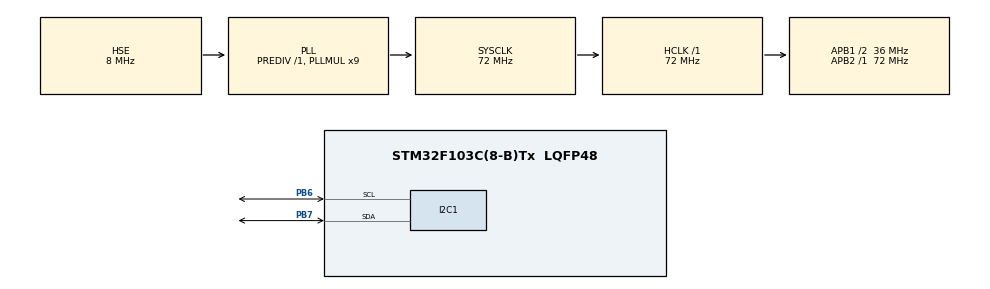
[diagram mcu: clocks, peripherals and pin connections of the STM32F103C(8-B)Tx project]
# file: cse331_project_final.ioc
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Mcu.Family=STM32F1
Mcu.Name=STM32F103C(8-B)Tx
Mcu.Package=LQFP48
NVIC.PriorityGroup=NVIC_PRIORITYGROUP_4
PA13.Mode=Serial_Wire
PA13.Signal=SYS_JTMS-SWDIO
PA14.Mode=Serial_Wire
PA14.Signal=SYS_JTCK-SWCLK
PB6.Mode=I2C
PB6.Signal=I2C1_SCL
PB7.Mode=I2C
PB7.Signal=I2C1_SDA
PD0-OSC_IN.Mode=HSE-External-Oscillator
PD0-OSC_IN.Signal=RCC_OSC_IN
PD1-OSC_OUT.Mode=HSE-External-Oscillator
PD1-OSC_OUT.Signal=RCC_OSC_OUT
ProjectManager.HeapSize=0x200
ProjectManager.StackSize=0x400
ProjectManager.TargetToolchain=STM32CubeIDE
RCC.AHBFreq_Value=72000000
RCC.APB1CLKDivider=RCC_HCLK_DIV2
RCC.APB1Freq_Value=36000000
RCC.APB1TimFreq_Value=72000000
RCC.APB2Freq_Value=72000000
RCC.APB2TimFreq_Value=72000000
RCC.HCLKFreq_Value=72000000
RCC.PLLMUL=RCC_PLL_MUL9
RCC.PLLSourceVirtual=RCC_PLLSOURCE_HSE
RCC.SYSCLKFreq_VALUE=72000000
RCC.SYSCLKSource=RCC_SYSCLKSOURCE_PLLCLK
RCC.USBFreq_Value=72000000
TIM1.Prescaler=71
VP_TIM1_VS_ClockSourceINT.Mode=Internal
board=custom

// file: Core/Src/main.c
/* USER CODE BEGIN Header */
/**
  ******************************************************************************
  * @file           : main.c
  * @brief          : Main program body
  ******************************************************************************
  * @attention
  *
  * Copyright (c) 2023 STMicroelectronics.
  * All rights reserved.
  *
  * This software is licensed under terms that can be found in the LICENSE file
  * in the root directory of this software component.
  * If no LICENSE file comes with this software, it is provided AS-IS.
  *
  ******************************************************************************
  */
/* USER CODE END Header */
#include "main.h"

/* USER CODE BEGIN Includes */
#include "i2c-lcd.h"
#include "stdio.h"
/* USER CODE END Includes */

I2C_HandleTypeDef hi2c1;

TIM_HandleTypeDef htim1;

void SystemClock_Config(void);
static void MX_GPIO_Init(void);
static void MX_I2C1_Init(void);
static void MX_TIM1_Init(void);

/* USER CODE BEGIN 0 */
#define DHT11_PORT GPIOB
#define DHT11_PIN GPIO_PIN_12
uint8_t RHI, RHD, TCI, TCD, SUM;
uint32_t pMillis, cMillis;
float tCelsius = 0;
float tFahrenheit = 0;
float RH = 0;
int row=0;
int col=0;
uint8_t TFI = 0;
uint8_t TFD = 0;
char strCopy1[40];
char strCopy2[40];

void microDelay (uint16_t delay)
{
  __HAL_TIM_SET_COUNTER(&htim1, 0);
  while (__HAL_TIM_GET_COUNTER(&htim1) < delay);
}

uint8_t DHT11_Start (void)
{
  uint8_t Response = 0;
  GPIO_InitTypeDef GPIO_InitStructPrivate = {0};
  GPIO_InitStructPrivate.Pin = DHT11_PIN;
  GPIO_InitStructPrivate.Mode = GPIO_MODE_OUTPUT_PP;
  GPIO_InitStructPrivate.Speed = GPIO_SPEED_FREQ_LOW;
  GPIO_InitStructPrivate.Pull = GPIO_NOPULL;
  HAL_GPIO_Init(DHT11_PORT, &GPIO_InitStructPrivate); // set the pin as output
  HAL_GPIO_WritePin (DHT11_PORT, DHT11_PIN, 0);   // pull the pin low
  HAL_Delay(20);   // wait for 20ms
  HAL_GPIO_WritePin (DHT11_PORT, DHT11_PIN, 1);   // pull the pin high
  microDelay (30);   // wait for 30us
  GPIO_InitStructPrivate.Mode = GPIO_MODE_INPUT;
  GPIO_InitStructPrivate.Pull = GPIO_PULLUP;
  HAL_GPIO_Init(DHT11_PORT, &GPIO_InitStructPrivate); // set the pin as input
  microDelay (40);
  if (!(HAL_GPIO_ReadPin (DHT11_PORT, DHT11_PIN)))
  {
    microDelay (80);
    if ((HAL_GPIO_ReadPin (DHT11_PORT, DHT11_PIN))) Response = 1;
  }
  pMillis = HAL_GetTick();
  cMillis = HAL_GetTick();
  while ((HAL_GPIO_ReadPin (DHT11_PORT, DHT11_PIN)) && pMillis + 2 > cMillis)
  {
    cMillis = HAL_GetTick();
  }
  return Response;
}

uint8_t DHT11_Read (void)
{
  uint8_t a,b;
  for (a=0;a<8;a++)
  {
    pMillis = HAL_GetTick();
    cMillis = HAL_GetTick();
    while (!(HAL_GPIO_ReadPin (DHT11_PORT, DHT11_PIN)) && pMillis + 2 > cMillis)
    {  // wait for the pin to go high
      cMillis = HAL_GetTick();
    }
    microDelay (40);   // wait for 40 us
    if (!(HAL_GPIO_ReadPin (DHT11_PORT, DHT11_PIN)))   // if the pin is low
      b&= ~(1<<(7-a));
    else
      b|= (1<<(7-a));
    pMillis = HAL_GetTick();
    cMillis = HAL_GetTick();
    while ((HAL_GPIO_ReadPin (DHT11_PORT, DHT11_PIN)) && pMillis + 2 > cMillis)
    {  // wait for the pin to go low
      cMillis = HAL_GetTick();
    }
  }
  return b;
}
/* USER CODE END 0 */

int main(void)
{

  /* MCU Configuration--------------------------------------------------------*/

  /* Reset of all peripherals, Initializes the Flash interface and the Systick. */
  HAL_Init();

  /* Configure the system clock */
  SystemClock_Config();

  /* Initialize all configured peripherals */
  MX_GPIO_Init();
  MX_I2C1_Init();
  MX_TIM1_Init();
  /* USER CODE BEGIN 2 */
    lcd_init ();

    lcd_send_string ("Welcome");

    HAL_Delay(1000);

    lcd_put_cur(1, 0);

    lcd_send_string("to CSE331");

    HAL_Delay(2000);

    lcd_clear ();
    HAL_TIM_Base_Start(&htim1);
  /* USER CODE END 2 */

  /* Infinite loop */
 while (1)
  {

    /* USER CODE BEGIN 3 */
	  if(DHT11_Start())
	      {
	        RHI = DHT11_Read(); // Relative humidity integral
	        RHD = DHT11_Read(); // Relative humidity decimal
	        TCI = DHT11_Read(); // Celsius integral
	        TCD = DHT11_Read(); // Celsius decimal
	        SUM = DHT11_Read(); // Check sum
	        if (RHI + RHD + TCI + TCD == SUM)
	        {

	          tCelsius = (float)TCI + (float)(TCD/10.0);
	          tFahrenheit = tCelsius * 9/5 + 32;
	          RH = (float)RHI + (float)(RHD/10.0);

	          sprintf(strCopy1,"Temp:%d.%d C", TCI,TCD);
	          lcd_put_cur(0, 0);
	          HAL_Delay(100);
	          lcd_send_string (strCopy1);
	              lcd_put_cur(1, 0);
	              sprintf(strCopy2,"Humidity:%d.%d %%", RHI,RHD);
	              lcd_send_string (strCopy2);
	              HAL_Delay(1000);

	        }

	        if (TCI >= 27)
	        {
	          //HAL_GPIO_WritePin(GPIOC, GPIO_PIN_13, 1);
	          HAL_GPIO_WritePin(GPIOB, GPIO_PIN_10, 1);
	          HAL_GPIO_WritePin(GPIOB, GPIO_PIN_11, 0);
	          //HAL_GPIO_WritePin(GPIOB, GPIO_PIN_1, 0);
	        }
	        if (TCI < 27)
	        	        {
	        	          HAL_GPIO_WritePin(GPIOB, GPIO_PIN_11, 1);
	        	          HAL_GPIO_WritePin(GPIOB, GPIO_PIN_10, 0);
	        	          //HAL_GPIO_WritePin(GPIOB, GPIO_PIN_14, 0);
	        	          //HAL_GPIO_WritePin(GPIOB, GPIO_PIN_1, 0);
	        	        }
	        else
	        {
	        	HAL_GPIO_WritePin(GPIOB, GPIO_PIN_11, 1);
	            HAL_GPIO_WritePin(GPIOB, GPIO_PIN_10, 1);
	        }
	      }
	      HAL_Delay(2000);

  }
  /* USER CODE END 3 */
}

void SystemClock_Config(void)
{
  RCC_OscInitTypeDef RCC_OscInitStruct = {0};
  RCC_ClkInitTypeDef RCC_ClkInitStruct = {0};

  /** Initializes the RCC Oscillators according to the specified parameters
  * in the RCC_OscInitTypeDef structure.
  */
  RCC_OscInitStruct.OscillatorType = RCC_OSCILLATORTYPE_HSE;
  RCC_OscInitStruct.HSEState = RCC_HSE_ON;
  RCC_OscInitStruct.HSEPredivValue = RCC_HSE_PREDIV_DIV1;
  RCC_OscInitStruct.HSIState = RCC_HSI_ON;
  RCC_OscInitStruct.PLL.PLLState = RCC_PLL_ON;
  RCC_OscInitStruct.PLL.PLLSource = RCC_PLLSOURCE_HSE;
  RCC_OscInitStruct.PLL.PLLMUL = RCC_PLL_MUL9;
  if (HAL_RCC_OscConfig(&RCC_OscInitStruct) != HAL_OK)
  {
    Error_Handler();
  }

  /** Initializes the CPU, AHB and APB buses clocks
  */
  RCC_ClkInitStruct.ClockType = RCC_CLOCKTYPE_HCLK|RCC_CLOCKTYPE_SYSCLK
                              |RCC_CLOCKTYPE_PCLK1|RCC_CLOCKTYPE_PCLK2;
  RCC_ClkInitStruct.SYSCLKSource = RCC_SYSCLKSOURCE_PLLCLK;
  RCC_ClkInitStruct.AHBCLKDivider = RCC_SYSCLK_DIV1;
  RCC_ClkInitStruct.APB1CLKDivider = RCC_HCLK_DIV2;
  RCC_ClkInitStruct.APB2CLKDivider = RCC_HCLK_DIV1;

  if (HAL_RCC_ClockConfig(&RCC_ClkInitStruct, FLASH_LATENCY_2) != HAL_OK)
  {
    Error_Handler();
  }
}

static void MX_I2C1_Init(void)
{

  hi2c1.Instance = I2C1;
  hi2c1.Init.ClockSpeed = 100000;
  hi2c1.Init.DutyCycle = I2C_DUTYCYCLE_2;
  hi2c1.Init.OwnAddress1 = 0;
  hi2c1.Init.AddressingMode = I2C_ADDRESSINGMODE_7BIT;
  hi2c1.Init.DualAddressMode = I2C_DUALADDRESS_DISABLE;
  hi2c1.Init.OwnAddress2 = 0;
  hi2c1.Init.GeneralCallMode = I2C_GENERALCALL_DISABLE;
  hi2c1.Init.NoStretchMode = I2C_NOSTRETCH_DISABLE;
  if (HAL_I2C_Init(&hi2c1) != HAL_OK)
  {
    Error_Handler();
  }

}

static void MX_TIM1_Init(void)
{

  TIM_ClockConfigTypeDef sClockSourceConfig = {0};
  TIM_MasterConfigTypeDef sMasterConfig = {0};

  htim1.Instance = TIM1;
  htim1.Init.Prescaler = 71;
  htim1.Init.CounterMode = TIM_COUNTERMODE_UP;
  htim1.Init.Period = 65535;
  htim1.Init.ClockDivision = TIM_CLOCKDIVISION_DIV1;
  htim1.Init.RepetitionCounter = 0;
  htim1.Init.AutoReloadPreload = TIM_AUTORELOAD_PRELOAD_DISABLE;
  if (HAL_TIM_Base_Init(&htim1) != HAL_OK)
  {
    Error_Handler();
  }
  sClockSourceConfig.ClockSource = TIM_CLOCKSOURCE_INTERNAL;
  if (HAL_TIM_ConfigClockSource(&htim1, &sClockSourceConfig) != HAL_OK)
  {
    Error_Handler();
  }
  sMasterConfig.MasterOutputTrigger = TIM_TRGO_RESET;
  sMasterConfig.MasterSlaveMode = TIM_MASTERSLAVEMODE_DISABLE;
  if (HAL_TIMEx_MasterConfigSynchronization(&htim1, &sMasterConfig) != HAL_OK)
  {
    Error_Handler();
  }

}

static void MX_GPIO_Init(void)
{

  /* GPIO Ports Clock Enable */
  __HAL_RCC_GPIOD_CLK_ENABLE();
  __HAL_RCC_GPIOA_CLK_ENABLE();
  __HAL_RCC_GPIOB_CLK_ENABLE();

}

void Error_Handler(void)
{
  __disable_irq();
  while (1)
  {
  }
}
